# STM32U3C5 register map
File version: 1.0
CPU: CM33 r0p1, little endian, MPU, FPU, 4 interrupt priority bits
Registers are 32-bit, read-write, reset 0x0 unless marked. A register's access mark holds for its fields unless they carry their own. Offsets are from the block's base; [hi:lo] are bit positions; 'fields as' and 'values as' point back to an identical list.

## IWDG — IWDG address block description
Base 0x40003000
Same registers: SEC_IWDG 0x50003000
0x00 IWDG_KR wo — IWDG key register
  [15:0] KEY — Key value (write only, read 0x0000)
0x04 IWDG_PR — IWDG prescaler register
  [3:0] PR — Prescaler divider
    0=divider / 4; 1=divider / 8; 2=divider / 16; 3=divider / 32; 4=divider / 64; 5=divider / 128; 6=divider / 256; 7=divider / 512
0x08 IWDG_RLR reset 0xFFF — IWDG reload register
  [11:0] RL — Watchdog counter reload value
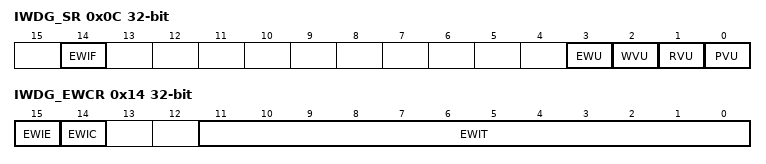
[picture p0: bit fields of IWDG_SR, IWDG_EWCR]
0x0C IWDG_SR ro — IWDG status register
  [14] EWIF — Watchdog early interrupt flag
  [3] EWU — Watchdog interrupt comparator value update
  [2] WVU — Watchdog counter window value update
  [1] RVU — Watchdog counter reload value update
  [0] PVU — Watchdog prescaler value update
0x10 IWDG_WINR reset 0xFFF — IWDG window register
  [11:0] WIN — Watchdog counter window value
0x14 IWDG_EWCR — IWDG early wake-up interrupt register
  [15] EWIE — Watchdog early interrupt enable
    0=The early interrupt interface is disabled; 1=The early interrupt interface is enabled
  [14] EWIC wo — Watchdog early interrupt acknowledge
  [11:0] EWIT — Watchdog counter window value

## OPAMP — OPAMP Address block
Base 0x40007000
Same registers: SEC_OPAMP 0x50007000
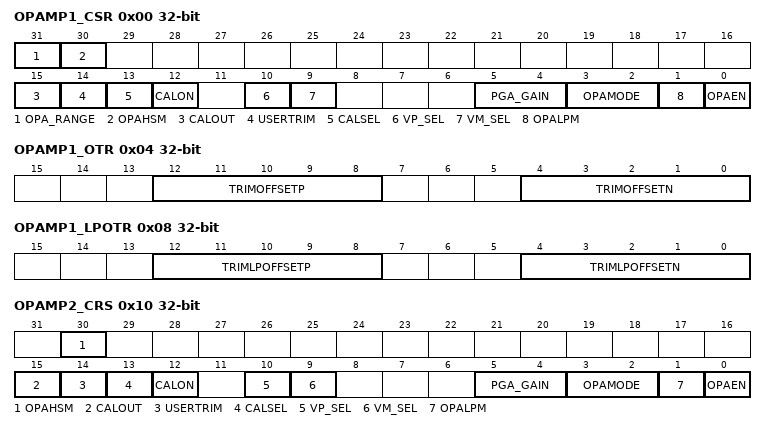
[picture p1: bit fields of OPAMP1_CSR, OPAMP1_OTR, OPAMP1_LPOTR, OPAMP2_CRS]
0x00 OPAMP1_CSR — OPAMP1 control/status register
  [31] OPA_RANGE — OPAMP range setting
    1=OPAMP range set
  [30] OPAHSM — OPAMP high-speed mode
    0=Normal mode (standard slew rate); 1=Increased consumption to improve the slew rate
  [15] CALOUT ro — OPAMP calibration output
  [14] USERTRIM — Selection of factory or user offset trimmed values
    0=Factory trim code used; 1=User trim code used
  [13] CALSEL — Calibration selection
    0=NMOS calibration (200mV applied on OPAMP inputs); 1=PMOS calibration (Vless thansub>DDA less than/sub>- 200 mV applied on OPAMP inputs)
  [12] CALON — Calibration mode enable
    0=Normal mode; 1=Calibration mode (all switches opened by hardware)
  [10] VP_SEL — Noninverted input selection
    0=GPIO connected to VINP; 1=DAC connected to VINP
  [9] VM_SEL — Inverting input selection
    0=GPIO connected to VINM (valid also in PGA mode for filtering); 1=Inverting input not externally connected
  [5:4] PGA_GAIN — OPAMP programmable amplifier gain value
    0=Internal PGA gain 2; 1=Internal PGA gain 4; 2=Internal PGA gain 8; 3=Internal PGA gain 16
  [3:2] OPAMODE — OPAMP PGA mode
    0=Internal PGA disabled; 1=Internal PGA disabled; 2=Internal PGA enabled, gain programmed in PGA_GAIN; 3=Internal follower
  [1] OPALPM — OPAMP low-power mode
    0=Normal mode; 1=Low-power mode
  [0] OPAEN — OPAMP enable
    0=OPAMP disabled; 1=OPAMP enabled
0x04 OPAMP1_OTR (reset mask 0xFFFF0000) — OPAMP1 offset trimming register in normal mode
  [12:8] TRIMOFFSETP — Trim for PMOS differential pairs
  [4:0] TRIMOFFSETN — Trim for NMOS differential pairs
0x08 OPAMP1_LPOTR (reset mask 0xFFFF0000) — OPAMP1 offset trimming register in low-power mode
  [12:8] TRIMLPOFFSETP — Low-power mode trim for PMOS differential pairs
  [4:0] TRIMLPOFFSETN — Low-power mode trim for NMOS differential pairs
0x10 OPAMP2_CRS — OPAMP2 control/status register
  [30] OPAHSM — OPAMP high-speed mode
    values as OPAMP1_CSR.OPAHSM
  [15] CALOUT ro — OPAMP calibration output
  [14] USERTRIM — Selection of factory or user offset trimmed values
    0=Factory trim code used; 1=User trim code used
  [13] CALSEL — Calibration selection
    0=NMOS calibration (200 mV applied on OPAMP inputs); 1=PMOS calibration (Vless thansub>DDA less than/sub>- 200 mV applied on OPAMP inputs)
  [12] CALON — Calibration mode enable
    values as OPAMP1_CSR.CALON
  [10] VP_SEL — Noninverted input selection
    0=GPIO connected to VINP; 1=DAC connected to VINP
  [9] VM_SEL — Inverting input selection
    values as OPAMP1_CSR.VM_SEL
  [5:4] PGA_GAIN — OPAMP programmable amplifier gain value
    values as OPAMP1_CSR.PGA_GAIN
  [3:2] OPAMODE — OPAMP PGA mode
    0=internal PGA disabled; 1=internal PGA disabled; 2=Internal PGA enabled, gain programmed in PGA_GAIN; 3=Internal follower
  [1] OPALPM — OPAMP low-power mode
    0=Normal mode; 1=Low-power mode
  [0] OPAEN — OPAMP enable
    0=OPAMP disabled; 1=OPAMP enabled
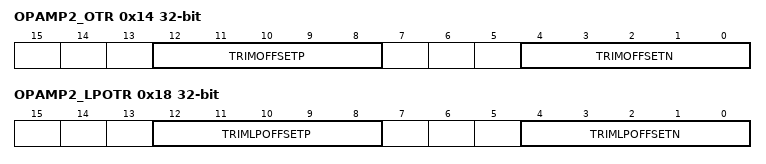
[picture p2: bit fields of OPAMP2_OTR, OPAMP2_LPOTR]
0x14 OPAMP2_OTR (reset mask 0xFFFF0000) — OPAMP2 offset trimming register in normal mode
  fields as OPAMP1_OTR
0x18 OPAMP2_LPOTR (reset mask 0xFFFF0000) — OPAMP2 offset trimming register in low-power mode
  fields as OPAMP1_LPOTR
